# ATBTLC1000WLCSP register map
Vendor: Atmel Corp; Series: SAMB11; File version: TODO
CPU: CM0 r0p0, little endian, no MPU, no FPU, 2 interrupt priority bits
Address unit: 32 bits
Registers are 32-bit, read-write, reset 0x0 unless marked. A register's access mark holds for its fields unless they carry their own. Offsets are from the block's base; [hi:lo] are bit positions; {n}, {i} and the like mark numbered series.

## ARM_SYSCTRL0 — ARM System Control
Base 0xE000E000
0x08 ACTLR ro — Auxiliary Control Register (not implemented)
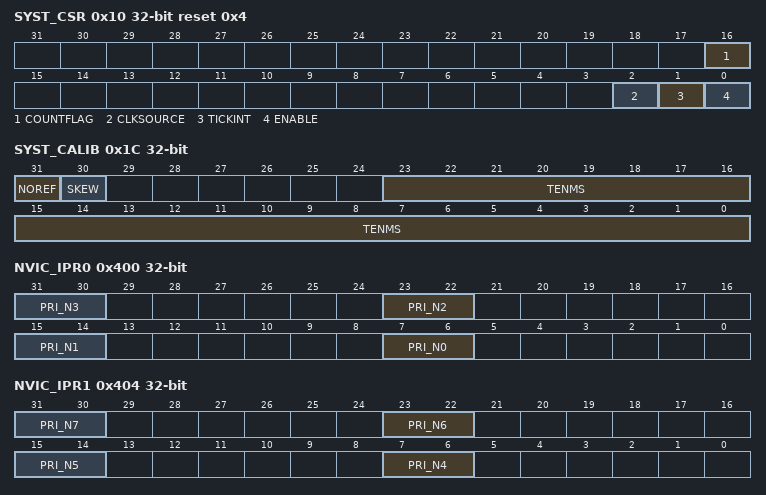
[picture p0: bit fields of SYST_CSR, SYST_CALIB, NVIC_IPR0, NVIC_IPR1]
0x10 SYST_CSR reset 0x4 — SysTick Control and Status Register
  [16] COUNTFLAG ro — If 1 then the timer has counted to 0
  [2] CLKSOURCE ro — SysTick uses the processor clock (writes are ignored)
  [1] TICKINT — Indicates whether counting to 0 causes the status of the SysTick exception to change to pending
    0=Count to 0 does not affect the SysTick exception status; 1=Count to 0 changes the SysTick excpetion status to pending
  [0] ENABLE — Indicates the enabled status of the SysTick counter
    0=Counter Disabled; 1=Counter Operating
0x14 SYST_RVR (reset mask 0xFFFFFF) — SysTick Reload Value Register
0x18 SYST_CVR (reset mask 0xFFFFFF) — SysTick Current Value Register (Any Write Clears to 0)
0x1C SYST_CALIB ro — SysTick Calibration Value Register
  [31] NOREF — If 1 then reference clock is not implemented
  [30] SKEW — If 1 then 10ms calibration value is inexact
  [23:0] TENMS — Holds a reload value to be used for 10ms timing. If 0 then calibration value is not known.
0x100 NVIC_ISER — Interrupt Set-Enable Register
  [31:0] SETENA — Write 1 to enable the associated interrupt
0x180 NVIC_ICER — Interrupt Clear Enable Register
  [31:0] CLRENA — Write 1 to disable the associated interrupt
0x200 NVIC_ISPR — Interrupt Set-Pending Register
  [31:0] SETPEND — Change the state of the associated interrupt to pending
0x280 NVIC_ICPR — Interrupt Clear-Pending Register
  [31:0] CLRPEND — Change the state of the associated interrupt to not pending
0x400 NVIC_IPR0 — Interrupt Priority Register 0
  [8n+7:8n+6] PRI_N{n} (n=0..3) — Priority of Interrupt {n}
0x404 NVIC_IPR1 — Interrupt Priority Register 1
  [8n-25:8n-26] PRI_N{n} (n=4..7) — Priority of Interrupt {n}
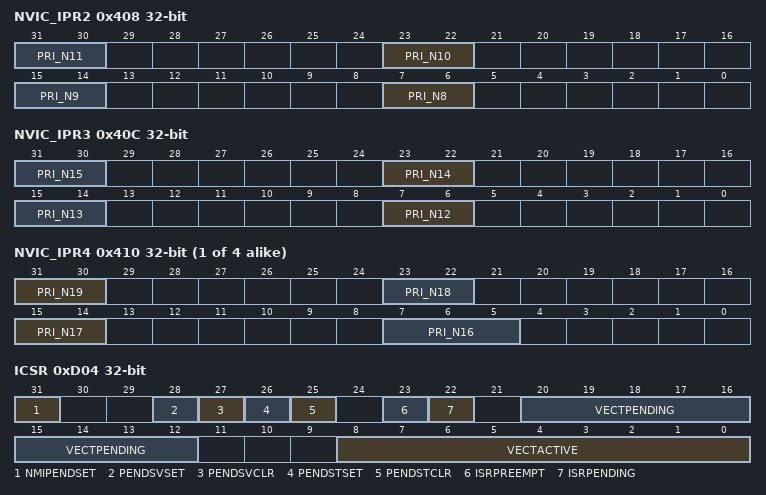
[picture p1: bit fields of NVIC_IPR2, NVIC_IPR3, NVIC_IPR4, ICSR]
0x408 NVIC_IPR2 — Interrupt Priority Register 2
  [8n-57:8n-58] PRI_N{n} (n=8..11) — Priority of Interrupt {n}
0x40C NVIC_IPR3 — Interrupt Priority Register 3
  [8n-89:8n-90] PRI_N{n} (n=12..15) — Priority of Interrupt {n}
{0x400+4i} NVIC_IPR{i} (i=4..7) — Interrupt Priority Register {i}
  [31:30] PRI_N{4i+3} — Priority of Interrupt {4i+3}
  [23:22] PRI_N{4i+2} — Priority of Interrupt {4i+2}
  [15:14] PRI_N{4i+1} — Priority of Interrupt {4i+1}
  [7:5] PRI_N{4i} — Priority of Interrupt {4i}
0xD00 CPUID ro reset 0x410CC200 — CPU Identification Register
0xD04 ICSR ro — Interrupt Control State Register
  [31] NMIPENDSET rw — Activate NMI Exception
  [28] PENDSVSET rw — Set pending PendSV interrupt
  [27] PENDSVCLR wo — Clearing pending PendSV
  [26] PENDSTSET rw — Set pending SysTick
  [25] PENDSTCLR wo — Clear Pending SysTick
  [23] ISRPREEMPT — If 1, will service a pending exception
  [22] ISRPENDING — If 1, Interrupt is pending
  [20:12] VECTPENDING — Exception number for highest priority pending exception
  [8:0] VECTACTIVE — Exception number for the current executing exception
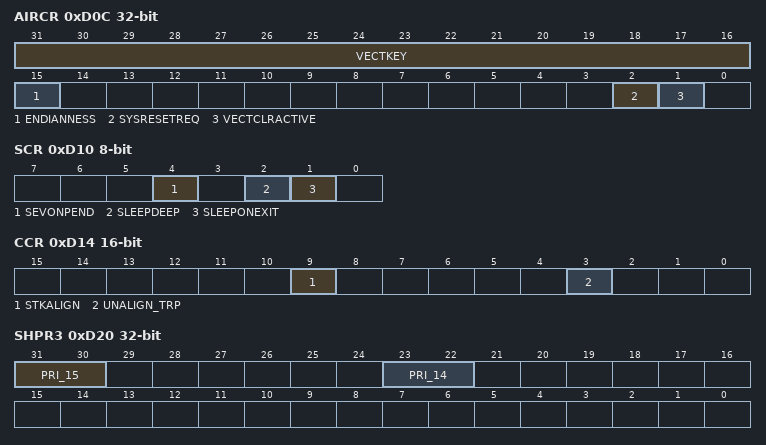
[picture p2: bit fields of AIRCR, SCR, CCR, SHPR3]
0xD0C AIRCR ro — Application Interrupt and Reset Control Register
  [31:16] VECTKEY rw — Vector Key, must write 0x05FA to this otherwise the write is UNPREDICTABLE
  [15] ENDIANNESS — If 1 then big endian
  [2] SYSRESETREQ wo — Active High System Reset Request
  [1] VECTCLRACTIVE wo — Clears all active state information for fixed and configurable exceptions
0xD10 SCR 8-bit — System Control Register
  [4] SEVONPEND — Transitions from inactive to pending are wakeup events
  [2] SLEEPDEEP — Selected sleep state is deep sleep
  [1] SLEEPONEXIT — Enter sleep state on exit from an ISR
0xD14 CCR 16-bit ro — Configuration and Control Register
  [9] STKALIGN — On exception entry, SP used prior to exception is adjusted to be 8-byte aligned and context to restore it is saved
  [3] UNALIGN_TRP — Unaligned work and halfword accesses generate a HardFault exception
0xD1C SHPR2 — System Handler Priority Register 2
  [31:30] PRI_11 — Priority of system handler 11, SVCall
0xD20 SHPR3 — System Handler Priority Register 3
  [31:30] PRI_15 — Priority of system handler 15, SysTick
  [23:22] PRI_14 — Priority of system handler 14, PendSV
0xD24 SHCSR 16-bit — System Handler Control and State Register
  [15] SVCALLPENDED — SVCall is pending
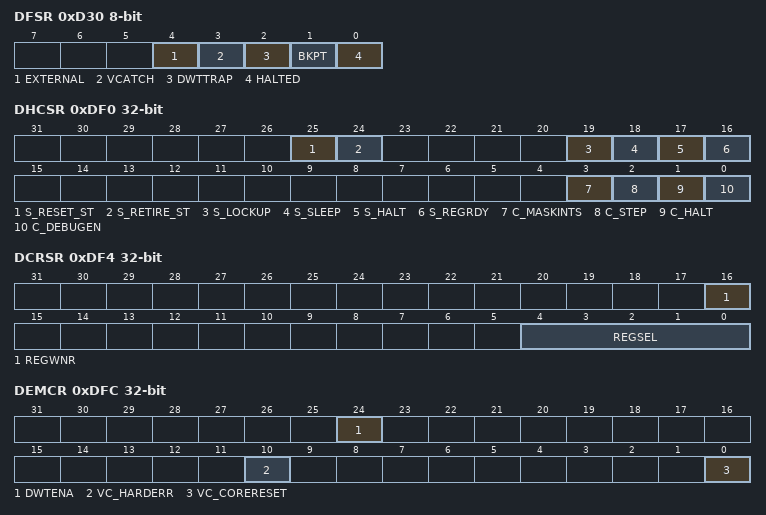
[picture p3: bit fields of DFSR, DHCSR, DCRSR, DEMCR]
0xD30 DFSR 8-bit — Debug Fault Status Register
  [4] EXTERNAL — EDBGRQ debug event
  [3] VCATCH — Vector catch debug event generated
  [2] DWTTRAP — At least one debug event generated by DWT
  [1] BKPT — At least one breakpoint debug event
  [0] HALTED — Halt Request Debug Event Active
0xDF0 DHCSR — Debug Halting Control and Status Register
  [25] S_RESET_ST ro — At least one reset since last DHCSR read
  [24] S_RETIRE_ST ro — At least one instruction has completed since last DHCSR read
  [19] S_LOCKUP ro — Locked Up
  [18] S_SLEEP ro — Sleeping
  [17] S_HALT ro — In Debug State
  [16] S_REGRDY ro — Transfer to or from the DCRDR is complete
  [3] C_MASKINTS — Mask PendSV, SysTick and external configurable interrupts (Must write 0xA05F to bits 31:16 to access)
  [2] C_STEP — Single-Stepping Enabled (Must write 0xA05F to bits 31:16 to access)
  [1] C_HALT — Request a running processor to halt (Must write 0xA05F to bits 31:16 to access)
  [0] C_DEBUGEN — Halting Debug Enabled (Must write 0xA05F to bits 31:16 to access)
0xDF4 DCRSR — Debug Core Register Selector Register
  [16] REGWNR — If 1 then transfer is a write
  [4:0] REGSEL — Specifies the ARM core register or special purpose register to transfer
    {v}=ARM Core Register R{v} (v=0..12); 13=Current SP; 14=LR; 15=DebugReturnAddress; 16=xPSR; 17=MSP; 18=PSP; 20=CONTROL and PRIMASK
0xDF8 DCRDR — Debug Core Register Data Register
  [31:0] DBGTMP — Data Temporary Cache
0xDFC DEMCR — Debug Exception and Monitor Control Register
  [24] DWTENA — DWT Enabled
  [10] VC_HARDERR — Halting Debug Trap Enabled
  [0] VC_CORERESET — Reset Vector Catch Enabled
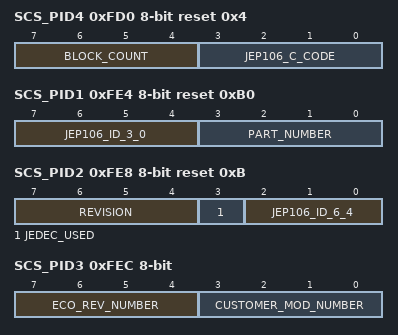
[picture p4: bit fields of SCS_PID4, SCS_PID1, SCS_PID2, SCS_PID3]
0xFD0 SCS_PID4 8-bit ro reset 0x4 — Peripheral ID Register 4
  [7:4] BLOCK_COUNT, [3:0] JEP106_C_CODE
0xFE0 SCS_PID0 8-bit ro reset 0x8 — Peripheral ID Register 0
  [7:0] PART_NUMBER — Part Number Bits 7:0
0xFE4 SCS_PID1 8-bit ro reset 0xB0 — Peripheral ID Register 1
  [7:4] JEP106_ID_3_0 — JEP106 ID Code Bits 3:0
  [3:0] PART_NUMBER — Part Number Bits 11:8
0xFE8 SCS_PID2 8-bit ro reset 0xB — Peripheral ID Register 2
  [7:4] REVISION
  [3] JEDEC_USED
  [2:0] JEP106_ID_6_4 — JEP106 ID Code Bits 6:4
0xFEC SCS_PID3 8-bit ro — Peripheral ID Register 3
  [7:4] ECO_REV_NUMBER — ECO Revision Number
  [3:0] CUSTOMER_MOD_NUMBER — Customer Modification Number
0xFF0 SCS_CID0 8-bit ro reset 0xD — Component ID Register 0
0xFF4 SCS_CID1 8-bit ro reset 0xE0 — Component ID Register 1
0xFF8 SCS_CID2 8-bit ro reset 0x5 — Component ID Register 2
0xFFC SCS_CID3 8-bit ro reset 0xB1 — Component ID Register 3
